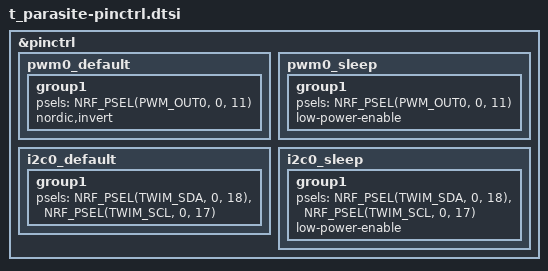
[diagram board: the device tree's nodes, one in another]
&pinctrl {
	/* PWM out: P0.11 */
	pwm0_default: pwm0_default {
		group1 {
			psels = <NRF_PSEL(PWM_OUT0, 0, 11)>;
			nordic,invert;
		};
	};

	pwm0_sleep: pwm0_sleep {
		group1 {
			psels = <NRF_PSEL(PWM_OUT0, 0, 11)>;
			low-power-enable;
		};
	};

	/* I2C: SDA = P0.18, SCL = P0.17 */
	i2c0_default: i2c0_default {
		group1 {
			psels = <NRF_PSEL(TWIM_SDA, 0, 18)>,
							<NRF_PSEL(TWIM_SCL, 0, 17)>;
		};
	};

	i2c0_sleep: i2c0_sleep {
		group1 {
			psels = <NRF_PSEL(TWIM_SDA, 0, 18)>,
							<NRF_PSEL(TWIM_SCL, 0, 17)>;
			low-power-enable;
		};
	};
};
